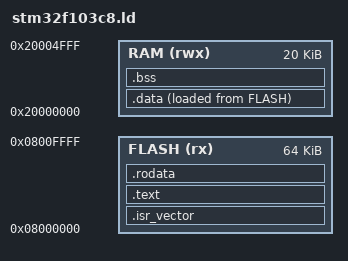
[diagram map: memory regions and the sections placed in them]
MEMORY
{
    FLASH (rx)  : ORIGIN = 0x08000000, LENGTH = 64K
    RAM   (rwx) : ORIGIN = 0x20000000, LENGTH = 20K
}

_estack = ORIGIN(RAM) + LENGTH(RAM);

SECTIONS
{
    .isr_vector :
    {
        . = ALIGN(4);
        KEEP(*(.isr_vector))
        . = ALIGN(4);
    } >FLASH

    .text :
    {
        . = ALIGN(4);
        *(.text)
        *(.text*)
        *(.glue_7)
        *(.glue_7t)
        KEEP(*(.init))
        KEEP(*(.fini))
        . = ALIGN(4);
        _etext = .;
    } >FLASH

    .rodata :
    {
        . = ALIGN(4);
        *(.rodata)
        *(.rodata*)
        . = ALIGN(4);
    } >FLASH

    _sidata = LOADADDR(.data);

    .data :
    {
        . = ALIGN(4);
        _sdata = .;
        *(.data)
        *(.data*)
        . = ALIGN(4);
        _edata = .;
    } >RAM AT> FLASH

    .bss :
    {
        . = ALIGN(4);
        _sbss = .;
        __bss_start__ = _sbss;
        *(.bss)
        *(.bss*)
        *(COMMON)
        . = ALIGN(4);
        _ebss = .;
        __bss_end__ = _ebss;
    } >RAM

    /DISCARD/ :
    {
        *(.ARM.attributes)
    }

    _end = .;
    PROVIDE(end = _end);
}
